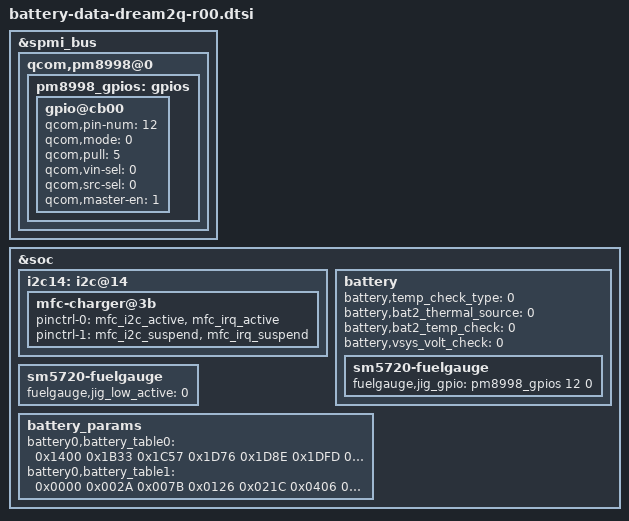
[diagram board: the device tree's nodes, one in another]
/* Copyright (c) 2014, The Linux Foundation. All rights reserved.
 *
 * This program is free software; you can redistribute it and/or modify
 * it under the terms of the GNU General Public License version 2 and
 * only version 2 as published by the Free Software Foundation.
 *
 * This program is distributed in the hope that it will be useful,
 * but WITHOUT ANY WARRANTY; without even the implied warranty of
 * MERCHANTABILITY or FITNESS FOR A PARTICULAR PURPOSE.  See the
 * GNU General Public License for more details.
 */
#include "battery-data-dream2q-common.dtsi"

&spmi_bus {
	qcom,pm8998@0 {
		pm8998_gpios: gpios {
			gpio@cb00 { /* PM8998 GPIO 12 for IFC_SENSE_INT_AP */
				status = "okay";
				qcom,pin-num = <12>;
				qcom,mode = <0>; /* QPNP_PIN_MODE_DIG_IN */
				qcom,pull = <5>; /* QPNP_PIN_PULL_NO */
				qcom,vin-sel = <0>; /* QPNP_PIN_VIN0 */
				qcom,src-sel = <0>; /* QPNP_PIN_SEL_FUNC_CONSTANT */
				qcom,master-en = <1>; /* Enable GPIO */
			};
		};
	};
};

&soc {

	i2c14: i2c@14 {	
		mfc-charger@3b {
			pinctrl-0 = <&mfc_i2c_active &mfc_irq_active>;
			pinctrl-1 = <&mfc_i2c_suspend &mfc_irq_suspend>;
		};
	};

	battery {
		battery,temp_check_type = <0>;

		battery,bat2_thermal_source = <0>;
		battery,bat2_temp_check = <0>;
		battery,vsys_volt_check = <0>;

		sm5720-fuelgauge {
			fuelgauge,jig_gpio = <&pm8998_gpios 12 0>; /* IFC_SENSE_INT_AP */
		};
	};

	sm5720-fuelgauge {
		fuelgauge,jig_low_active = <0>;
	};

	battery_params {
		battery0,battery_table0 = <0x1400 0x1B33 0x1C57 0x1D76 0x1D8E 0x1DFD 0x1E9F 0x1EF3 0x1F5F 0x1FAB 0x1FD9 0x200C 0x206D 0x20F1 0x224E 0x2399>;
		battery0,battery_table1 = <0x0000 0x002A 0x007B 0x0126 0x021C 0x0406 0x08D1 0x0A41 0x0B36 0x0C2B 0x0D21 0x0D9B 0x0E16 0x0F86 0x1266 0x1274>;
	};
};
